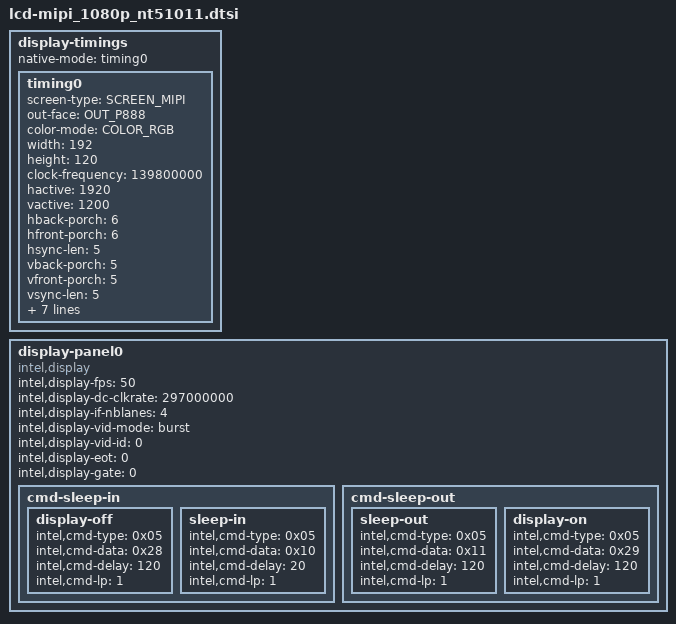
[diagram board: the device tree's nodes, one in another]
/*
 * sofia. lcd-mipi_nt51011.dtsi
 * this file include the definition about screen timing and init msg
 * macro definition at "include/dt-bindings/sofiafb/sofia_fb.h"
 */

	display-timings {
		native-mode = <&timing0>;
		timing0: timing0 {
			screen-type = <SCREEN_MIPI>;
			out-face    = <OUT_P888>;
			color-mode = <COLOR_RGB>;
			width = <192>;
			height = <120>;
			clock-frequency = <139800000>;
			hactive = <1920>;
			vactive = <1200>;
			hback-porch = <6>;
			hfront-porch = <6>;
			hsync-len = <5>;
			vback-porch = <5>;
			vfront-porch = <5>;
			vsync-len = <5>;
			hsync-active = <0>;
			vsync-active = <0>;
			de-active = <0>;
			pixelclk-active = <0>;
			swap-rb = <0>;
			swap-rg = <0>;
			swap-gb = <0>;
		};
	};

	display-panel0 {
		compatible = "intel,display";

		/* intel,display-ramless = <1>; */
		intel,display-fps = <50>;
		intel,display-dc-clkrate = <297000000>;
		intel,display-if-nblanes = <4>;
		intel,display-vid-mode = "burst";
		intel,display-vid-id = <0>;
		intel,display-eot = <0>;
		intel,display-gate = <0>;

		/* cmd-init { }; */

		cmd-sleep-in {
			display-off {
				intel,cmd-type = <0x05>;
				intel,cmd-data = <0x28>;
				intel,cmd-delay = <120>;
				intel,cmd-lp = <1>;
			};
			sleep-in {
				intel,cmd-type = <0x05>;
				intel,cmd-data = <0x10>;
				intel,cmd-delay = <20>;
				intel,cmd-lp = <1>;
			};
		};

		cmd-sleep-out {
			sleep-out {
				intel,cmd-type = <0x05>;
				intel,cmd-data = <0x11>;
				intel,cmd-delay = <120>;
				intel,cmd-lp = <1>;
			};
			display-on {
				intel,cmd-type = <0x05>;
				intel,cmd-data = <0x29>;
				intel,cmd-delay = <120>;
				intel,cmd-lp = <1>;
			};
		};
	};
